# STM32WBAxx register map
File version: 0.1
Registers are 32-bit, read-write, reset 0x0 unless marked. A register's access mark holds for its fields unless they carry their own. Offsets are from the block's base; [hi:lo] are bit positions; {n}, {i} and the like mark numbered series; 'fields as' and 'values as' point back to an identical list.

## RCC (part 3 of 3) — Reset and clock control
Base 0x46020C00
Same registers: SEC_RCC 0x56020C00
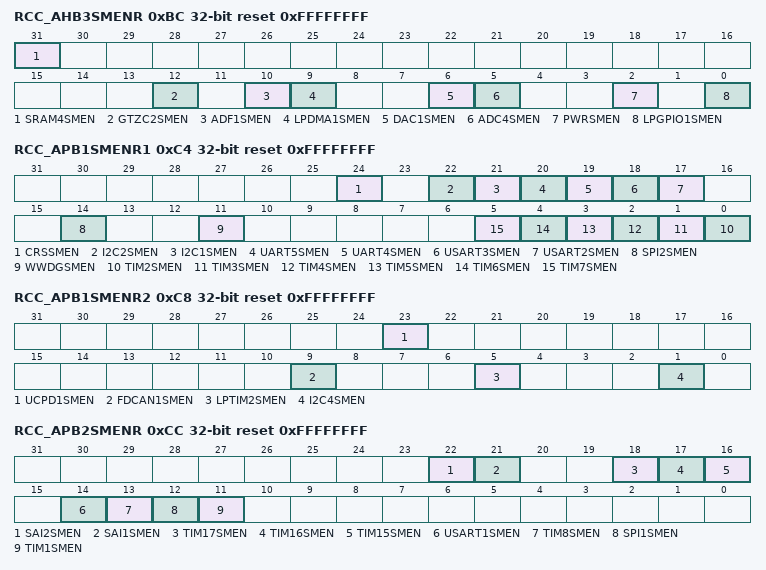
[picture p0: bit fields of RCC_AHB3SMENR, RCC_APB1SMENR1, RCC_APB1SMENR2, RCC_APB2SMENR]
0xBC RCC_AHB3SMENR reset 0xFFFFFFFF — RCC AHB3 peripheral clocks enable in Sleep and Stop modes register
  [31] SRAM4SMEN — SRAM4 clocks enable during Sleep and Stop modes Set and cleared by software.
    0=SRAM4 clocks disabled by the clock gating during Sleep and Stop modes; 1=SRAM4 clocks enabled by the clock gating during Sleep and Stop modes
  [12] GTZC2SMEN — GTZC2 clock enable during Sleep and Stop modes Set and cleared by software.
    0=GTZC2 clock disabled by the clock gating during Sleep and Stop modes; 1=GTZC2 clock enabled by the clock gating during Sleep and Stop modes
  [10] ADF1SMEN — ADF1 clock enable during Sleep and Stop modes Set and cleared by software. Note: This bit must be set to allow the peripheral to wake up from Stop modes.
    0=ADF1 clock disabled by the clock gating during Sleep and Stop modes; 1=ADF1 clock enabled by the clock gating during Sleep and Stop modes
  [9] LPDMA1SMEN — LPDMA1 clock enable during Sleep and Stop modes Set and cleared by software. Note: This bit must be set to allow the peripheral to wake up from Stop modes.
    0=LPDMA1 clock disabled by the clock gating during Sleep and Stop modes; 1=LPDMA1 clock enabled by the clock gating during Sleep and Stop modes
  [6] DAC1SMEN — DAC1 clock enable during Sleep and Stop modes Set and cleared by software. Note: This bit must be set to allow the peripheral to wake up from Stop modes.
    0=DAC1 clock disabled by the clock gating during Sleep and Stop modes; 1=DAC1 clock enabled by the clock gating during Sleep and Stop modes
  [5] ADC4SMEN — ADC4 clock enable during Sleep and Stop modes Set and cleared by software. Note: This bit must be set to allow the peripheral to wake up from Stop modes.
    0=ADC4 clock disabled by the clock gating during Sleep and Stop modes; 1=ADC4 clock enabled by the clock gating during Sleep and Stop modes
  [2] PWRSMEN — PWR clock enable during Sleep and Stop modes Set and cleared by software.
    0=PWR clock disabled by the clock gating during Sleep and Stop modes; 1=PWR clock enabled by the clock gating during Sleep and Stop modes
  [0] LPGPIO1SMEN — LPGPIO1 enable during Sleep and Stop modes Set and cleared by software.
    0=LPGPIO1 clock disabled by the clock gating during Sleep and Stop modes; 1=LPGPIO1 clock enabled by the clock gating during Sleep and Stop modes
0xC4 RCC_APB1SMENR1 reset 0xFFFFFFFF — RCC APB1 peripheral clocks enable in Sleep and Stop modes register 1
  [24] CRSSMEN — CRS clock enable during Sleep and Stop modes Set and cleared by software.
    0=CRS clocks disabled by the clock gating during Sleep and Stop modes; 1=CRS clocks enabled by the clock gating during Sleep and Stop modes
  [22] I2C2SMEN — I2C2 clocks enable during Sleep and Stop modes Set and cleared by software. Note: This bit must be set to allow the peripheral to wake up from Stop modes.
    0=I2C2 clocks disabled by the clock gating during Sleep and Stop modes; 1=I2C2 clocks enabled by the clock gating during Sleep and Stop modes
  [21] I2C1SMEN — I2C1 clocks enable during Sleep and Stop modes Set and cleared by software. Note: This bit must be set to allow the peripheral to wake up from Stop modes.
    0=I2C1 clocks disabled by the clock gating during Sleep and Stop modes; 1=I2C1 clocks enabled by the clock gating during Sleep and Stop modes
  [20] UART5SMEN — UART5 clocks enable during Sleep and Stop modes Set and cleared by software. Note: This bit must be set to allow the peripheral to wake up from Stop modes.
    0=UART5 clocks disabled by the clock gating during Sleep and Stop modes; 1=UART5 clocks enabled by the clock gating during Sleep and Stop modes
  [19] UART4SMEN — UART4 clocks enable during Sleep and Stop modes Set and cleared by software. Note: This bit must be set to allow the peripheral to wake up from Stop modes.
    0=UART4 clocks disabled by the clock gating during Sleep and Stop modes; 1=UART4 clocks enabled by the clock gating during Sleep and Stop modes
  [18] USART3SMEN — USART3 clocks enable during Sleep and Stop modes Set and cleared by software. Note: This bit must be set to allow the peripheral to wake up from Stop modes.
    0=USART3 clocks disabled by the clock gating during Sleep and Stop modes; 1=USART3 clocks enabled by the clock gating during Sleep and Stop modes
  [17] USART2SMEN — USART2 clocks enable during Sleep and Stop modes Set and cleared by software. Note: This bit must be set to allow the peripheral to wake up from Stop modes.
    0=USART2 clocks disabled by the clock gating during Sleep and Stop modes; 1=USART2 clocks enabled by the clock gating during Sleep and Stop modes
  [14] SPI2SMEN — SPI2 clocks enable during Sleep and Stop modes Set and cleared by software. Note: This bit must be set to allow the peripheral to wake up from Stop modes.
    0=SPI2 clocks disabled by the clock gating during Sleep and Stop modes; 1=SPI2 clocks enabled by the clock gating during Sleep and Stop modes
  [11] WWDGSMEN — Window watchdog clocks enable during Sleep and Stop modes Set and cleared by software. This bit is forced to 1 by hardware when the hardware WWDG option is activated.
    0=Window watchdog clocks disabled by the clock gating during Sleep and Stop modes; 1=Window watchdog clocks enabled by the clock gating during Sleep and Stop modes
  [n-2] TIM{n}SMEN (n=2..7) — TIM{n} clocks enable during Sleep and Stop modes Set and cleared by software.
    0=TIM{n} clocks disabled by the clock gating during Sleep and Stop modes; 1=TIM{n} clocks enabled by the clock gating during Sleep and Stop modes
0xC8 RCC_APB1SMENR2 reset 0xFFFFFFFF — RCC APB1 peripheral clocks enable in Sleep and Stop modes register 2
  [23] UCPD1SMEN — UCPD1 clocks enable during Sleep and Stop modes Set and cleared by software.
    0=UCPD1 clocks disabled by the clock gating during Sleep and Stop modes; 1=UCPD1 clocks enabled by the clock gating during Sleep and Stop modes
  [9] FDCAN1SMEN — FDCAN1 clocks enable during Sleep and Stop modes Set and cleared by software.
    0=FDCAN1 clocks disabled by the clock gating during Sleep and Stop modes; 1=FDCAN1 clocks enabled by the clock gating during Sleep and Stop modes
  [5] LPTIM2SMEN — LPTIM2 clocks enable during Sleep and Stop modes Set and cleared by software. Note: This bit must be set to allow the peripheral to wake up from Stop modes.
    0=LPTIM2 clocks disabled by the clock gating during Sleep and Stop modes; 1=LPTIM2 clocks enabled by the clock gating during Sleep and Stop modes
  [1] I2C4SMEN — I2C4 clocks enable during Sleep and Stop modes Set and cleared by software Note: This bit must be set to allow the peripheral to wake up from Stop modes.
    0=I2C4 clocks disabled by the clock gating during Sleep and Stop modes; 1=I2C4 clocks enabled by the clock gating during Sleep and Stop modes
0xCC RCC_APB2SMENR reset 0xFFFFFFFF — RCC APB2 peripheral clocks enable in Sleep and Stop modes register
  [22] SAI2SMEN — SAI2 clocks enable during Sleep and Stop modes Set and cleared by software.
    0=SAI2 clocks disabled by the clock gating during Sleep and Stop modes; 1=SAI2 clocks enabled by the clock gating during Sleep and Stop modes
  [21] SAI1SMEN — SAI1 clocks enable during Sleep and Stop modes Set and cleared by software.
    0=SAI1 clocks disabled by the clock gating during Sleep and Stop modes; 1=SAI1 clocks enabled by the clock gating during Sleep and Stop modes
  [18] TIM17SMEN — TIM17 clocks enable during Sleep and Stop modes Set and cleared by software.
    0=TIM17 clocks disabled by the clock gating during Sleep and Stop modes; 1=TIM17 clocks enabled by the clock gating during Sleep and Stop modes
  [17] TIM16SMEN — TIM16 clocks enable during Sleep and Stop modes Set and cleared by software.
    0=TIM16 clocks disabled by the clock gating during Sleep and Stop modes; 1=TIM16 clocks enabled by the clock gating during Sleep and Stop modes
  [16] TIM15SMEN — TIM15 clocks enable during Sleep and Stop modes Set and cleared by software.
    0=TIM15 clocks disabled by the clock gating during Sleep and Stop modes; 1=TIM15 clocks enabled by the clock gating during Sleep and Stop modes
  [14] USART1SMEN — USART1clocks enable during Sleep and Stop modes Set and cleared by software. Note: This bit must be set to allow the peripheral to wake up from Stop modes.
    0=USART1clocks disabled by the clock gating during Sleep and Stop modes; 1=USART1clocks enabled by the clock gating during Sleep and Stop modes
  [13] TIM8SMEN — TIM8 clocks enable during Sleep and Stop modes Set and cleared by software.
    0=TIM8 clocks disabled by the clock gating during Sleep and Stop modes; 1=TIM8 clocks enabled by the clock gating during Sleep and Stop modes
  [12] SPI1SMEN — SPI1 clocks enable during Sleep and Stop modes Set and cleared by software. Note: This bit must be set to allow the peripheral to wake up from Stop modes.
    0=SPI1 clocks disabled by the clock gating during Sleep and Stop modes; 1=SPI1 clocks enabled by the clock gating during Sleep and Stop modes
  [11] TIM1SMEN — TIM1 clocks enable during Sleep and Stop modes Set and cleared by software.
    0=TIM1 clocks disabled by the clock gating during Sleep and Stop modes; 1=TIM1 clocks enabled by the clock gating during Sleep and Stop modes
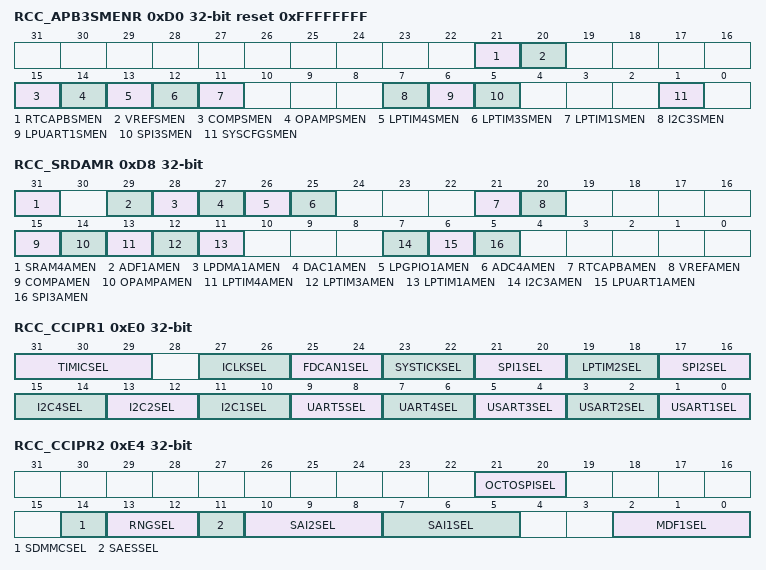
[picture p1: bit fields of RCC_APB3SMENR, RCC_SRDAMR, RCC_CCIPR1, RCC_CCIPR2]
0xD0 RCC_APB3SMENR reset 0xFFFFFFFF — RCC APB3 peripheral clock enable in Sleep and Stop modes register
  [21] RTCAPBSMEN — RTC and TAMP APB clock enable during Sleep and Stop modes Set and cleared by software. Note: This bit must be set to allow the peripheral to wake up from Stop modes.
    0=RTC and TAMP APB clock disabled by the clock gating during Sleep and Stop modes; 1=RTC and TAMP APB clock enabled by the clock gating during Sleep and Stop modes
  [20] VREFSMEN — VREFBUF clocks enable during Sleep and Stop modes Set and cleared by software.
    0=VREFBUF clocks disabled by the clock gating during Sleep and Stop modes; 1=VREFBUF clocks enabled by the clock gating during Sleep and Stop modes
  [15] COMPSMEN — COMP clocks enable during Sleep and Stop modes Set and cleared by software.
    0=COMP clocks disabled by the clock gating during Sleep and Stop modes; 1=COMP clocks enabled by the clock gating during Sleep and Stop modes
  [14] OPAMPSMEN — OPAMP clocks enable during Sleep and Stop modes Set and cleared by software.
    0=OPAMP clocks disabled by the clock gating during Sleep and Stop modes; 1=OPAMP clocks enabled by the clock gating during Sleep and Stop modes
  [13] LPTIM4SMEN — LPTIM4 clocks enable during Sleep and Stop modes Set and cleared by software. Note: This bit must be set to allow the peripheral to wake up from Stop modes.
    0=LPTIM4 clocks disabled by the clock gating during Sleep and Stop modes; 1=LPTIM4 clocks enabled by the clock gating during Sleep and Stop modes
  [12] LPTIM3SMEN — LPTIM3 clocks enable during Sleep and Stop modes Set and cleared by software. Note: This bit must be set to allow the peripheral to wake up from Stop modes.
    0=LPTIM3 clocks disabled by the clock gating during Sleep and Stop modes; 1=LPTIM3 clocks enabled by the clock gating during Sleep and Stop modes
  [11] LPTIM1SMEN — LPTIM1 clocks enable during Sleep and Stop modes Set and cleared by software. Note: This bit must be set to allow the peripheral to wake up from Stop modes.
    0=LPTIM1 clocks disabled by the clock gating during Sleep and Stop modes; 1=LPTIM1 clocks enabled by the clock gating during Sleep and Stop modes
  [7] I2C3SMEN — I2C3 clocks enable during Sleep and Stop modes Set and cleared by software. Note: This bit must be set to allow the peripheral to wake up from Stop modes.
    0=I2C3 clocks disabled by the clock gating during Sleep and Stop modes; 1=I2C3 clocks enabled by the clock gating during Sleep and Stop modes
  [6] LPUART1SMEN — LPUART1 clocks enable during Sleep and Stop modes Set and cleared by software. Note: This bit must be set to allow the peripheral to wake up from Stop modes.
    0=LPUART1 clocks disabled by the clock gating during Sleep and Stop modes; 1=LPUART1 clocks enabled by the clock gating during Sleep and Stop modes
  [5] SPI3SMEN — SPI3 clocks enable during Sleep and Stop modes Set and cleared by software. Note: This bit must be set to allow the peripheral to wake up from Stop modes.
    0=SPI3 clocks disabled by the clock gating during Sleep and Stop modes; 1=SPI3 clocks enabled by the clock gating during Sleep and Stop modes
  [1] SYSCFGSMEN — SYSCFG clocks enable during Sleep and Stop modes Set and cleared by software.
    0=SYSCFG clocks disabled by the clock gating during Sleep and Stop modes; 1=SYSCFG clocks enabled by the clock gating during Sleep and Stop modes
0xD8 RCC_SRDAMR — RCC SmartRun domain peripheral autonomous mode register
  [31] SRAM4AMEN — SRAM4 autonomous mode enable in Stop 0,1,2 mode Set and cleared by software.
    0=SRAM4 autonomous mode disabled during Stop 0,1,2 mode; 1=SRAM4 autonomous mode enabled during Stop 0,1,2 mode
  [29] ADF1AMEN — ADF1 autonomous mode enable in Stop 0,1,2 mode Set and cleared by software. Note: This bit must be set to allow the peripheral to wake up from Stop modes.
    0=ADF1 autonomous mode disabled during Stop 0,1,2 mode; 1=ADF1 autonomous mode enabled during Stop 0,1,2 mode
  [28] LPDMA1AMEN — LPDMA1 autonomous mode enable in Stop 0,1,2 mode Set and cleared by software. Note: This bit must be set to allow the peripheral to wake up from Stop modes.
    0=LPDMA1 autonomous mode disabled during Stop 0,1,2 mode; 1=LPDMA1 autonomous mode enabled during Stop 0,1,2 mode
  [27] DAC1AMEN — DAC1 autonomous mode enable in Stop 0,1,2 mode Set and cleared by software. Note: This bit must be set to allow the peripheral to wake up from Stop modes.
    0=DAC1 autonomous mode disabled during Stop 0,1,2 mode; 1=DAC1 autonomous mode enabled during Stop 0,1,2 mode
  [26] LPGPIO1AMEN — LPGPIO1 autonomous mode enable in Stop 0,1,2 mode Set and cleared by software.
    0=LPGPIO1 autonomous mode disabled during Stop 0,1,2 mode; 1=LPGPIO1 autonomous mode enabled during Stop 0,1,2 mode
  [25] ADC4AMEN — ADC4 autonomous mode enable in Stop 0,1,2 mode Set and cleared by software. Note: This bit must be set to allow the peripheral to wake up from Stop modes.
    0=ADC4 autonomous mode disabled during Stop 0,1,2 mode; 1=ADC4 autonomous mode enabled during Stop 0,1,2 mode
  [21] RTCAPBAMEN — RTC and TAMP autonomous mode enable in Stop 0,1,2 mode Set and cleared by software. Note: This bit must be set to allow the peripheral to wake up from Stop modes.
    0=RTC and TAMP autonomous mode disabled during Stop 0,1,2 mode; 1=RTC and TAMP autonomous mode enabled during Stop 0,1,2 mode
  [20] VREFAMEN — VREFBUF autonomous mode enable in Stop 0,1,2 mode Set and cleared by software.
    0=VREFBUF autonomous mode disabled during Stop 0,1,2 mode; 1=VREFBUF autonomous mode enabled during Stop 0,1,2 mode
  [15] COMPAMEN — COMP autonomous mode enable in Stop 0,1,2 mode Set and cleared by software.
    0=COMP autonomous mode disabled during Stop 0,1,2 mode; 1=COMP autonomous mode enabled during Stop 0,1,2 mode
  [14] OPAMPAMEN — OPAMP autonomous mode enable in Stop 0,1,2 mode Set and cleared by software.
    0=OPAMP autonomous mode disabled during Stop 0,1,2 mode; 1=OPAMP autonomous mode enabled during Stop 0,1,2 mode
  [13] LPTIM4AMEN — LPTIM4 autonomous mode enable in Stop 0,1,2 mode Set and cleared by software. Note: This bit must be set to allow the peripheral to wake up from Stop modes.
    0=LPTIM4 autonomous mode disabled during Stop 0,1,2 mode; 1=LPTIM4 autonomous mode enabled during Stop 0,1,2 mode
  [12] LPTIM3AMEN — LPTIM3 autonomous mode enable in Stop 0,1,2 mode Set and cleared by software. Note: This bit must be set to allow the peripheral to wake up from Stop modes.
    0=LPTIM3 autonomous mode disabled during Stop 0,1,2 mode; 1=LPTIM3 autonomous mode enabled during Stop 0,1,2 mode
  [11] LPTIM1AMEN — LPTIM1 autonomous mode enable in Stop 0,1,2 mode Set and cleared by software. Note: This bit must be set to allow the peripheral to wake up from Stop modes.
    0=LPTIM1 autonomous mode disabled during Stop 0,1,2 mode; 1=LPTIM1 autonomous mode enabled during Stop 0,1,2 mode
  [7] I2C3AMEN — I2C3 autonomous mode enable in Stop 0,1,2 mode Set and cleared by software. Note: This bit must be set to allow the peripheral to wake up from Stop modes.
    0=I2C3 autonomous mode disabled during Stop 0,1,2 mode; 1=I2C3 autonomous mode enabled during Stop 0,1,2 mode
  [6] LPUART1AMEN — LPUART1 autonomous mode enable in Stop 0,1, 2 mode Set and cleared by software. Note: This bit must be set to allow the peripheral to wake up from Stop modes.
    0=LPUART1 autonomous mode disabled during Stop 0,1,2 mode; 1=LPUART1 autonomous mode enabled during Stop 0,1,2 mode
  [5] SPI3AMEN — SPI3 autonomous mode enable in Stop 0,1, 2 mode Set and cleared by software. Note: This bit must be set to allow the peripheral to wake up from Stop modes.
    0=SPI3 autonomous mode disabled during Stop 0,1,2 mode; 1=SPI3 autonomous mode enabled during Stop 0,1,2 mode
0xE0 RCC_CCIPR1 — RCC peripherals independent clock configuration register 1
  [31:29] TIMICSEL — Clocks sources for TIM16,TIM17 and LPTIM2 internal input capture When the TIMICSEL2 bit is set, the TIM16, TIM17 and LPTIM2 internal input capture can be connected either to HSI/256, MSI/4 or MSI/1024. Depending on TIMICSEL[1:0] value, MSI is either MSIK or MSIS. When TIMICSEL2 is cleared, the HSI, MSIK and MSIS clock sources cannot be selected as TIM16, TIM17 or LPTIM2 internal input capture. 0xx: HSI, MSIK and MSIS dividers disabled Note: The clock division must be disabled (TIMICSEL configured to 0xx) before selecting or changing a clock sources division.
    4=HSI/256, MSIS/1024 and MSIS/4 generated and can be selected by TIM16, TIM17 and LPTIM2 as internal input capture; 5=HSI/256, MSIS/1024 and MSIK/4 generated and can be selected by TIM16, TIM17 and LPTIM2 as internal input capture; 6=HSI/256, MSIK/1024 and MSIS/4 generated and can be selected by TIM16, TIM17 and LPTIM2 as internal input capture; 7=HSI/256, MSIK/1024 and MSIK/4 generated and can be selected by TIM16, TIM17 and LPTIM2 as internal input capture
  [27:26] ICLKSEL — intermediate clock source selection These bits are used to select the clock source used by OTG_FS and SDMMC.
    0=HSI48 clock selected; 1=PLL2 Q (pll2_q_ck) selected; 2=PLL1 Q (pll1_q_ck) selected; 3=MSIK clock selected
  [25:24] FDCAN1SEL — FDCAN1 kernel clock source selection These bits are used to select the FDCAN1 kernel clock source.
    0=HSE clock selected; 1=PLL1Q (pll1_q_ck) selected; 2=PLL2 P (pll2_p_ck) selected
  [23:22] SYSTICKSEL — SysTick clock source selection These bits are used to select the SysTick clock source. Note: When LSE or LSI is selected, the AHB frequency must be at least four times higher than the LSI or LSE frequency. In addition, a jitter up to one HCLK cycle is introduced, due to the LSE or LSI sampling with HCLK in the SysTick circuitry.
    0=HCLK/8 selected; 1=LSI selected; 2=LSE selected
  [21:20] SPI1SEL — SPI1 kernel clock source selection These bits are used to select the SPI1 kernel clock source. Note: The SPI1 is functional in Stop 0 and Stop 1 mode only when the kernel clock is HSI16 or MSIK.
    0=PCLK2 selected; 1=SYSCLK selected; 2=HSI16 selected; 3=MSIK selected
  [19:18] LPTIM2SEL — Low-power timer 2 kernel clock source selection These bits are used to select the LPTIM2 kernel clock source. Note: The LPTIM2 is functional in Stop 0 and Stop 1 mode only when the kernel clock is LSI, LSE or HSI16 if HSIKERON = 1.
    0=PCLK1 selected; 1=LSI selected; 2=HSI16 selected; 3=LSE selected
  [17:16] SPI2SEL — SPI2 kernel clock source selection These bits are used to select the SPI2 kernel clock source. Note: The SPI2 is functional in Stop 0 and Stop 1 mode only when the kernel clock is HSI16 or MSIK.
    0=PCLK1 selected; 1=SYSCLK selected; 2=HSI16 selected; 3=MSIK selected
  [15:14] I2C4SEL — I2C4 kernel clock source selection These bits are used to select the I2C4 kernel clock source. Note: The I2C4 is functional in Stop 0 and Stop 1 mode only when the kernel clock is HSI16 or MSIK.
    values as SPI2SEL
  [13:12] I2C2SEL — I2C2 kernel clock source selection These bits are used to select the I2C2 kernel clock source. Note: The I2C2 is functional in Stop 0 and Stop 1 mode only when the kernel clock is HSI16 or MSIK.
    values as SPI2SEL
  [11:10] I2C1SEL — I2C1 kernel clock source selection These bits are used to select the I2C1 kernel clock source. Note: The I2C1 is functional in Stop 0 and Stop 1 mode only when the kernel clock is HSI16 or MSIK.
    values as SPI2SEL
  [9:8] UART5SEL — UART5 kernel clock source selection These bits are used to select the UART5 kernel clock source. Note: The UART5 is functional in Stop 0 and Stop 1 mode only when the kernel clock is HSI16 or LSE.
    0=PCLK1 selected; 1=SYSCLK selected; 2=HSI16 selected; 3=LSE selected
  [7:6] UART4SEL — UART4 kernel clock source selection This bits are used to select the UART4 kernel clock source. Note: The UART4 is functional in Stop 0 and Stop 1 mode only when the kernel clock is HSI16 or LSE.
    values as UART5SEL
  [5:4] USART3SEL — USART3 kernel clock source selection This bits are used to select the USART3 kernel clock source. Note: The USART3 is functional in Stop 0 and Stop 1 mode only when the kernel clock is HSI16 or LSE.
    values as UART5SEL
  [3:2] USART2SEL — USART2 kernel clock source selection This bits are used to select the USART2 kernel clock source. Note: The USART2 is functional in Stop 0 and Stop 1 mode only when the kernel clock is HSI16 or LSE.
    values as UART5SEL
  [1:0] USART1SEL — USART1 kernel clock source selection This bits are used to select the USART1 kernel clock source. Note: The USART1 is functional in Stop 0 and Stop 1 mode only when the kernel clock is HSI16 or LSE.
    0=PCLK2 selected; 1=SYSCLK selected; 2=HSI16 selected; 3=LSE selected
0xE4 RCC_CCIPR2 — RCC peripherals independent clock configuration register 2
  [21:20] OCTOSPISEL — OCTOSPI1 and OCTOSPI2 kernel clock source selection These bits are used to select the OCTOSPI1 and OCTOSPI2 kernel clock source.
    0=SYSCLK selected; 1=MSIK selected; 2=PLL1 Q (pll1_q_ck) selected, can be up to 200 MHz; 3=PLL2 Q (pll2_q_ck) selected, can be up to 200 MHz
  [14] SDMMCSEL — SDMMC1 and SDMMC2 kernel clock source selection This bit is used to select the SDMMC kernel clock source. It is recommended to change this bit only after reset and before enabling the SDMMC.
    0=ICLK clock selected; 1=PLL1 P (pll1_p_ck) selected, in case higher than 48 MHz is needed (for SDR50 mode)
  [13:12] RNGSEL — RNGSEL kernel clock source selection These bits are used to select the RNG kernel clock source.
    0=HSI48 selected; 1=HSI48 / 2 selected, can be used in Range 4; 2=HSI16 selected
  [11] SAESSEL — SAES kernel clock source selection This bit is used to select the SAES kernel clock source.
    0=SHSI selected; 1=SHSI / 2 selected, can be used in Range 4
  [10:8] SAI2SEL — SAI2 kernel clock source selection These bits are used to select the SAI2 kernel clock source. others: reserved Note: If the selected clock is the external clock and this clock is stopped, a switch to another clock is impossible.
    0=PLL2 P (pll2_p_ck) selected; 1=PLL3 P (pll3_p_ck) selected; 2=PLL1 P (pll1_p_ck) selected; 3=input pin AUDIOCLK selected; 4=HSI16 clock selected
  [7:5] SAI1SEL — SAI1 kernel clock source selection These bits are used to select the SAI1 kernel clock source. others: reserved Note: If the selected clock is the external clock and this clock is stopped, a switch to another clock is impossible.
    values as SAI2SEL
  [2:0] MDF1SEL — MDF1 kernel clock source selection These bits are used to select the MDF1 kernel clock source. others: reserved
    0=HCLK selected; 1=PLL1 P (pll1_p_ck) selected; 2=PLL3 Q (pll3_q_ck) selected; 3=input pin AUDIOCLK selected; 4=MSIK clock selected
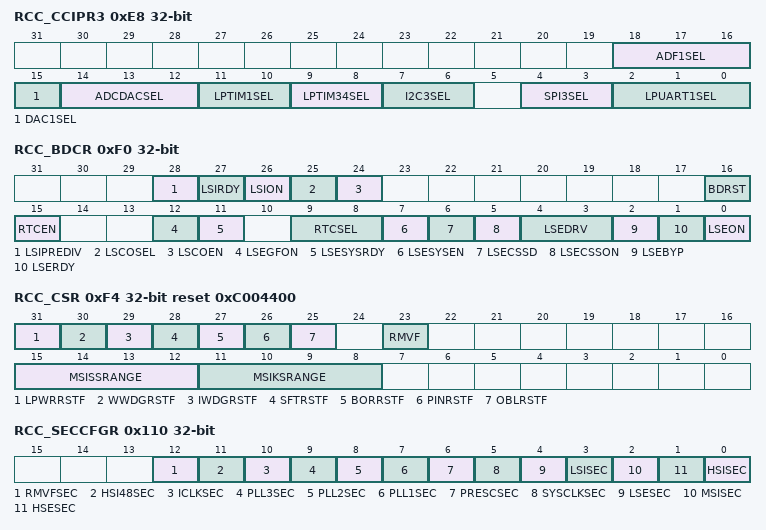
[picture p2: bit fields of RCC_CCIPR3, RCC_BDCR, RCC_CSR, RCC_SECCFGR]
0xE8 RCC_CCIPR3 — RCC peripherals independent clock configuration register 3
  [18:16] ADF1SEL — ADF1 kernel clock source selection These bits are used to select the ADF1 kernel clock source. others: reserved Note: The ADF1 is functional in Stop 0, Stop 1 and Stop 2 modes only when the kernel clock is AUDIOCLK or MSIK.
    values as RCC_CCIPR2.MDF1SEL
  [15] DAC1SEL — DAC1 sample and hold clock source selection This bit is used to select the DAC1 sample and hold clock source.
    0=LSE selected; 1=LSI selected
  [14:12] ADCDACSEL — ADC1, ADC4 and DAC1 kernel clock source selection These bits are used to select the ADC1, ADC4 and DAC1 kernel clock source. others: reserved Note: The ADC1, ADC4 and DAC1 are functional in Stop 0, Stop 1 and Stop 2 modes only when the kernel clock is HSI16 or MSIK (only ADC4 and DAC1 are functional in Stop 2 mode).
    0=HCLK clock selected; 1=SYSCLK selected; 2=PLL2 R (pll2_r_ck) selected; 3=HSE clock selected; 4=HSI16 clock selected; 5=MSIK clock selected
  [11:10] LPTIM1SEL — LPTIM1 kernel clock source selection These bits are used to select the LPTIM1 kernel clock source. Note: The LPTIM1 is functional in Stop 0, Stop 1 and Stop 2 modes only when the kernel clock is LSI, LSE, HSI16 with HSIKERON = 1 or MSIK with MSIKERON = 1.
    0=MSIK clock selected; 1=LSI selected; 2=HSI16 selected; 3=LSE selected
  [9:8] LPTIM34SEL — LPTIM3 and LPTIM4 kernel clock source selection These bits are used to select the LPTIM3 and LPTIM4 kernel clock source. Note: The LPTIM3 and LPTIM4 are functional in Stop 0, Stop 1 and Stop 2 modes only when the kernel clock is LSI, LSE, HSI16 with HSIKERON = 1 or MSIK with MSIKERON = 1.
    0=MSIK clock selected; 1=LSI selected; 2=HSI selected; 3=LSE selected
  [7:6] I2C3SEL — I2C3 kernel clock source selection These bits are used to select the I2C3 kernel clock source. Note: The I2C3 is functional in Stop 0, Stop 1 and Stop 2 modes only when the kernel clock is HSI16 or MSIK.
    0=PCLK3 selected; 1=SYSCLK selected; 2=HSI16 selected; 3=MSIK selected
  [4:3] SPI3SEL — SPI3 kernel clock source selection These bits are used to select the SPI3 kernel clock source. Note: The SPI3 is functional in Stop 0, Stop 1 and Stop 2 modes only when the kernel clock is HSI16 or MSIK.
    values as I2C3SEL
  [2:0] LPUART1SEL — LPUART1 kernel clock source selection These bits are used to select the LPUART1 kernel clock source. others: reserved Note: The LPUART1 is functional in Stop 0, Stop 1 and Stop 2 modes only when the kernel clock is HSI16, LSE or MSIK.
    0=PCLK3 selected; 1=SYSCLK selected; 2=HSI16 selected; 3=LSE selected; 4=MSIK selected
0xF0 RCC_BDCR access per field — RCC Backup domain control register
  [28] LSIPREDIV rw — Low-speed clock divider configuration Set and cleared by software to enable the LSI division. This bit can be written only when the LSI is disabled (LSION = 0 and LSIRDY = 0). If the LSI was previously enabled, it is necessary to wait for at least 60 Î¼s after clearing LSION bit (synchronization time for LSI to be really disabled), before writing LSIPREDIV. The LSIPREDIV cannot be changed if the LSI is used by the IWDG or by the RTC.
    0=LSI not divided; 1=LSI divided by 128
  [27] LSIRDY rw — LSI oscillator ready Set and cleared by hardware to indicate when the LSI oscillator is stable. After the LSION bit is cleared, LSIRDY goes low after three internal low-speed oscillator clock cycles. This bit is set when the LSI is used by IWDG or RTC, even if LSION = 0.
    0=LSI oscillator not ready; 1=LSI oscillator ready
  [26] LSION rw — LSI oscillator enable Set and cleared by software.
    0=LSI oscillator OFF; 1=LSI oscillator ON
  [25] LSCOSEL rw — Low-speed clock output selection Set and cleared by software.
    0=LSI clock selected; 1=LSE clock selected
  [24] LSCOEN rw — Low-speed clock output (LSCO) enable Set and cleared by software.
    0=LSCO disabled; 1=LSCO enabled
  [16] BDRST rw — Backup domain software reset Set and cleared by software.
    0=Reset not activated; 1=Reset the entire Backup domain
  [15] RTCEN rw — RTC and TAMP clock enable Set and cleared by software.
    0=RTC and TAMP clock disabled; 1=RTC and TAMP clock enabled
  [12] LSEGFON rw — LSE clock glitch filter enable Set and cleared by hardware to enable the LSE glitch filter. This bit can be written only when the LSE is disabled (LSEON = 0 and LSERDY = 0)
    0=LSE glitch filter disabled; 1=LSE glitch filter enabled
  [11] LSESYSRDY ro — LSE system clock (LSESYS) ready Set and cleared by hardware to indicate when the LSE system clock is stable.When the LSESYSEN bit is set, the LSESYSRDY flag is set after two LSE clock cycles. The LSE clock must be already enabled and stable (LSEON and LSERDY are set). When the LSEON bit is cleared, LSERDY goes low after six external low-speed oscillator clock cycles.
    0=LSESYS clock not ready; 1=LSESYS clock ready
  [9:8] RTCSEL rw — RTC and TAMP clock source selection Set by software to select the clock source for the RTC and TAMP . Once the RTC and TAMP clock source has been selected, it cannot be changed anymore unless the Backup domain is reset, or unless a failure is detected on LSE (LSECSSD is set). The BDRST bit can be used to reset them.
    0=No clock selected; 1=LSE oscillator clock selected; 2=LSI oscillator clock selected; 3=HSE oscillator clock divided by 32 selected
  [7] LSESYSEN rw — LSE system clock (LSESYS) enable Set by software to enable always the LSE system clock generated by RCC. This clock can be used by any peripheral when its source clock is the LSE or at system level in case of one of the LSCOSEL, MCO, MSI PLL mode or CSS on LSE is needed. The LSESYS clock can be generated even if LSESYSEN= 0 if the LSE clock is requested by the CSS on LSE, by a peripheral or any other source clock using LSE.
    0=LSESYS only enabled when requested by a peripheral or system function; 1=LSESYS enabled always generated by the RCC
  [6] LSECSSD ro — CSS on LSE failure Detection Set by hardware to indicate when a failure is detected by the CCS on the external 32 kHz oscillator (LSE).
    0=No failure detected on LSE; 1=Failure detected on LSE
  [5] LSECSSON rw — CSS on LSE enable Set by software to enable the CSS on LSE. LSECSSON must be enabled after the LSE oscillator is enabled (LSEON bit enabled) and ready (LSERDY flag set by hardware), and after the RTCSEL bit is selected. Once enabled, this bit cannot be disabled, except after a LSE failure detection (LSECSSD = 1). In that case, the software must disable the LSECSSON bit.
    0=CSS on LSE OFF; 1=CSS on LSE ON
  [4:3] LSEDRV rw — LSE oscillator drive capability Set by software to modulate the drive capability of the LSE oscillator. This field can be written only when the external 32 kHz oscillator is disabled (LSEON = 0 and LSERDY = 0). Note: The oscillator is in 'Xtal mode when it is not in bypass mode.
    0='Xtal mode lower driving capability; 1='Xtal mode medium-low driving capability; 2='Xtal mode medium-high driving capability; 3='Xtal mode higher driving capability
  [2] LSEBYP rw — LSE oscillator bypass Set and cleared by software to bypass oscillator in debug mode. This bit can be written only when the external 32 kHz oscillator is disabled (LSEON = 0 and LSERDY = 0).
    0=LSE oscillator not bypassed; 1=LSE oscillator bypassed
  [1] LSERDY ro — LSE oscillator ready Set and cleared by hardware to indicate when the external 32 kHz oscillator is stable. After the LSEON bit is cleared, LSERDY goes low after six external low-speed oscillator clock cycles.
    0=LSE oscillator not ready; 1=LSE oscillator ready
  [0] LSEON rw — LSE oscillator enable Set and cleared by software.
    0=LSE oscillator OFF; 1=LSE oscillator ON
0xF4 RCC_CSR access per field reset 0xC004400 — RCC control/status register
  [31] LPWRRSTF ro — Low-power reset flag Set by hardware when a reset occurs due to Stop, Standby or Shutdown mode entry, whereas the corresponding nRST_STOP, nRST_STBY or nRST_SHDW option bit is cleared. Cleared by writing to the RMVF bit.
    0=No illegal low-power mode reset occurred; 1=Illegal low-power mode reset occurred
  [30] WWDGRSTF ro — Window watchdog reset flag Set by hardware when a window watchdog reset occurs. Cleared by writing to the RMVF bit.
    0=No window watchdog reset occurred; 1=Window watchdog reset occurred
  [29] IWDGRSTF ro — Independent watchdog reset flag Set by hardware when an independent watchdog reset domain occurs. Cleared by writing to the RMVF bit.
    0=No independent watchdog reset occurred; 1=Independent watchdog reset occurred
  [28] SFTRSTF ro — Software reset flag Set by hardware when a software reset occurs. Cleared by writing to the RMVF bit.
    0=No software reset occurred; 1=Software reset occurred
  [27] BORRSTF ro — BOR flag Set by hardware when a BOR occurs. Cleared by writing to the RMVF bit.
    0=No BOR occurred; 1=BOR occurred
  [26] PINRSTF ro — NRST pin reset flag Set by hardware when a reset from the NRST pin occurs. Cleared by writing to the RMVF bit.
    0=No reset from NRST pin occurred; 1=Reset from NRST pin occurred
  [25] OBLRSTF ro — Option byte loader reset flag Set by hardware when a reset from the option byte loading occurs. Cleared by writing to the RMVF bit.
    0=No reset from option byte loading occurred; 1=Reset from option byte loading occurred
  [23] RMVF rw — Remove reset flag Set by software to clear the reset flags.
    0=No effect; 1=Clear the reset flags
  [15:12] MSISSRANGE rw — MSIS range after Standby mode Set by software to chose the MSIS frequency at startup. This range is used after exiting Standby mode until MSIRGSEL is set. After a NRST pin or a power-on reset or when exiting Shutdown mode, the range is always 4 MHz. MSISSRANGE can be written only when MSIRGSEL = 1. others: reserved Note: Changing the MSISSRANGE does not change the current MSIS frequency.
    4=range 4 around 4M Hz (reset value); 5=range 5 around 2 MHz; 6=range 6 around 1.5 MHz; 7=range 7 around 1 MHz; 8=range 8 around 3.072 MHz
  [11:8] MSIKSRANGE rw — MSIK range after Standby mode Set by software to chose the MSIK frequency at startup. This range is used after exiting Standby mode until MSIRGSEL is set. After a NRST pin or a power-on reset or when exiting Shutdown mode, the range is always 4 MHz. MSIKSRANGE can be written only when MSIRGSEL = 1. others: reserved Note: Changing the MSIKSRANGE does not change the current MSIK frequency.
    values as MSISSRANGE
0x110 RCC_SECCFGR — RCC secure configuration register
  [all] fields
    0=non secure; 1=secure
  [12] RMVFSEC — Remove reset flag security Set and reset by software.
  [11] HSI48SEC — HSI48 clock configuration and status bits security Set and reset by software.
  [10] ICLKSEC — intermediate clock source selection security Set and reset by software.
  [9] PLL3SEC — PLL3 clock configuration and status bits security Set and reset by software.
  [8] PLL2SEC — PLL2 clock configuration and status bits security Set and reset by software.
  [7] PLL1SEC — PLL1 clock configuration and status bits security Set and reset by software.
  [6] PRESCSEC — AHBx/APBx prescaler configuration bits security Set and reset by software.
  [5] SYSCLKSEC — SYSCLK clock selection, STOPWUCK bit, clock output on MCO configuration security Set and reset by software.
  [4] LSESEC — LSE clock configuration and status bits security Set and reset by software.
  [3] LSISEC — LSI clock configuration and status bits security Set and reset by software.
  [2] MSISEC — MSI clock configuration and status bits security Set and reset by software.
  [1] HSESEC — HSE clock configuration bits, status bits and HSE_CSS security Set and reset by software.
  [0] HSISEC — HSI clock configuration and status bits security Set and reset by software.
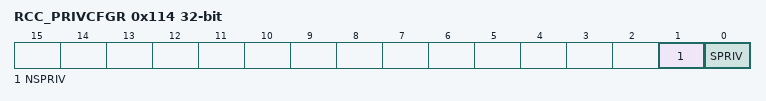
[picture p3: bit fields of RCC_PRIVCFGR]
0x114 RCC_PRIVCFGR — RCC privilege configuration register
  [1] NSPRIV — RCC non-secure functions privilege configuration Set and reset by software. This bit can be written only by privileged access, secure or non-secure.
    0=Read and write to RCC non-secure functions can be done by privileged or unprivileged access; 1=Read and write to RCC non-secure functions can be done by privileged access only
  [0] SPRIV — RCC secure functions privilege configuration Set and reset by software. This bit can be written only by a secure privileged access.
    0=Read and write to RCC secure functions can be done by privileged or unprivileged access; 1=Read and write to RCC secure functions can be done by privileged access only
